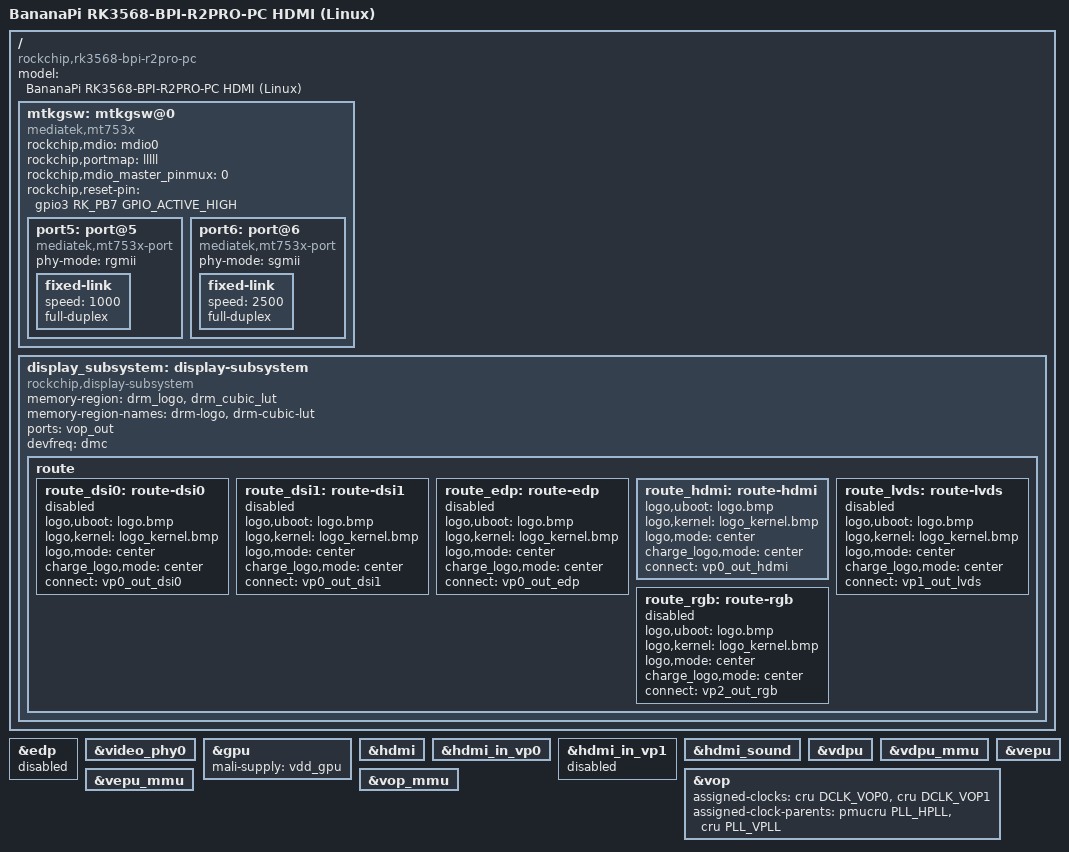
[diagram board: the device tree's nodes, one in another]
// SPDX-License-Identifier: (GPL-2.0+ OR MIT)
/*
 * Copyright (c) 2020 Rockchip Electronics Co., Ltd.
 *
 */

/dts-v1/;

#include "rk3568-bpi-r2pro-pc.dtsi"

/ {
    model = "BananaPi RK3568-BPI-R2PRO-PC HDMI (Linux)";
    compatible = "rockchip,rk3568-bpi-r2pro-pc", "rockchip,rk3568";

     mtkgsw: mtkgsw@0 {
	     compatible = "mediatek,mt753x";
	     rockchip,mdio = <&mdio0>;
	     rockchip,portmap = "lllll";
	     rockchip,mdio_master_pinmux = <0>;
	     rockchip,reset-pin = <&gpio3 RK_PB7 GPIO_ACTIVE_HIGH>;
	     status = "okay";

             port5: port@5 {
                     compatible = "mediatek,mt753x-port";
//                     reg = <5>;
                     phy-mode = "rgmii";
                     fixed-link {
                             speed = <1000>;
                             full-duplex;
                    };
            };

            port6: port@6 {
                    compatible = "mediatek,mt753x-port";
 //                   reg = <6>;
                    phy-mode = "sgmii";
                    fixed-link {
                            speed = <2500>;
                            full-duplex;
                   };
           };
     };

	display_subsystem: display-subsystem {
		compatible = "rockchip,display-subsystem";
		memory-region = <&drm_logo>, <&drm_cubic_lut>;
		memory-region-names = "drm-logo", "drm-cubic-lut";
		ports = <&vop_out>;
		devfreq = <&dmc>;

		route {
			route_dsi0: route-dsi0 {
				status = "disabled";
				logo,uboot = "logo.bmp";
				logo,kernel = "logo_kernel.bmp";
				logo,mode = "center";
				charge_logo,mode = "center";
				connect = <&vp0_out_dsi0>;
			};
			route_dsi1: route-dsi1 {
				status = "disabled";
				logo,uboot = "logo.bmp";
				logo,kernel = "logo_kernel.bmp";
				logo,mode = "center";
				charge_logo,mode = "center";
				connect = <&vp0_out_dsi1>;
			};
			route_edp: route-edp {
				status = "disabled";
				logo,uboot = "logo.bmp";
				logo,kernel = "logo_kernel.bmp";
				logo,mode = "center";
				charge_logo,mode = "center";
				connect = <&vp0_out_edp>;
			};
			route_hdmi: route-hdmi {
				status = "disabled";
				logo,uboot = "logo.bmp";
				logo,kernel = "logo_kernel.bmp";
				logo,mode = "center";
				charge_logo,mode = "center";
				connect = <&vp1_out_hdmi>;
			};
			route_lvds: route-lvds {
				status = "disabled";
				logo,uboot = "logo.bmp";
				logo,kernel = "logo_kernel.bmp";
				logo,mode = "center";
				charge_logo,mode = "center";
				connect = <&vp1_out_lvds>;
			};
			route_rgb: route-rgb {
				status = "disabled";
				logo,uboot = "logo.bmp";
				logo,kernel = "logo_kernel.bmp";
				logo,mode = "center";
				charge_logo,mode = "center";
				connect = <&vp2_out_rgb>;
			};
		};
	};
};

&edp {
	status = "disabled";
};

&video_phy0 {
	status = "okay";
};

&display_subsystem {
    status = "okay";
};

&gpu {
	mali-supply = <&vdd_gpu>;
	status = "okay";
};

&hdmi {
	status = "okay";
};

&hdmi_in_vp0 {
	status = "okay";
};

&hdmi_in_vp1 {
	status = "disabled";
};

&hdmi_sound {
	status = "okay";
};

&route_hdmi {
    status = "okay";
    connect = <&vp0_out_hdmi>;
};

&vdpu {
	status = "okay";
};

&vdpu_mmu {
	status = "okay";
};

&vepu {
	status = "okay";
};

&vepu_mmu {
	status = "okay";
};

&vop {
	status = "okay";
	assigned-clocks = <&cru DCLK_VOP0>, <&cru DCLK_VOP1>;
	assigned-clock-parents = <&pmucru PLL_HPLL>, <&cru PLL_VPLL>;
};

&vop_mmu {
	status = "okay";
};
